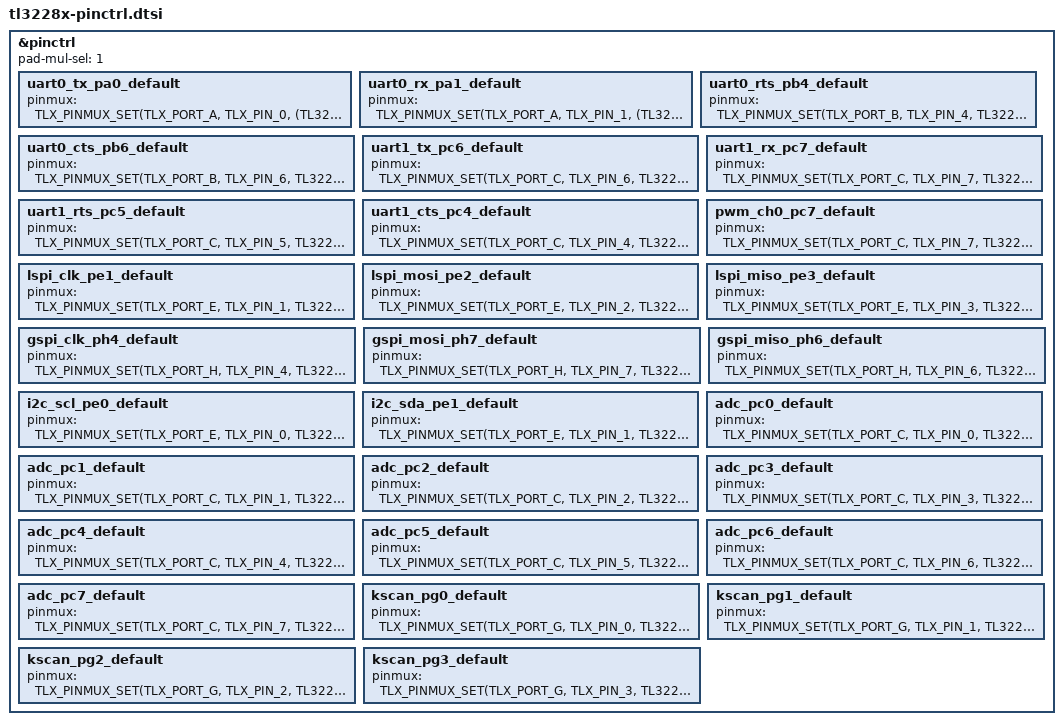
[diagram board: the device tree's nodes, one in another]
/*
 * Copyright (c) 2024 Telink Semiconductor
 *
 * SPDX-License-Identifier: Apache-2.0
 */

#include <zephyr/dt-bindings/pinctrl/tl322x-pinctrl.h>

&pinctrl {
	/* Set pad-mul-sel register value.
	 * Note: Pins functions below (pinmux = <...>) depend on this value.
	 */
	pad-mul-sel = <1>;

	/* UART0: TX(PA0), RX(PA1), RTS(PB4), CTS(PB6) */

	uart0_tx_pa0_default: uart0_tx_pa0_default {
		pinmux = <TLX_PINMUX_SET(TLX_PORT_A, TLX_PIN_0,
			(TL322X_FUNC_UART0_TX))>;
	};
	uart0_rx_pa1_default: uart0_rx_pa1_default {
		pinmux = <TLX_PINMUX_SET(TLX_PORT_A, TLX_PIN_1,
			(TL322X_FUNC_UART0_RTX_IO))>;
	};
	uart0_rts_pb4_default: uart0_rts_pb4_default {
		pinmux = <TLX_PINMUX_SET(TLX_PORT_B, TLX_PIN_4, TL322X_FUNC_UART0_RTS)>;
	};
	uart0_cts_pb6_default: uart0_cts_pb6_default {
		pinmux = <TLX_PINMUX_SET(TLX_PORT_B, TLX_PIN_6, TL322X_FUNC_UART0_CTS_I)>;
	};

	/* UART1: TX(PC6), RX(PC7), RTS(PC5), CTS(PC4) */

	uart1_tx_pc6_default: uart1_tx_pc6_default {
		pinmux = <TLX_PINMUX_SET(TLX_PORT_C, TLX_PIN_6, TL322X_FUNC_UART1_TX)>;
	};
	uart1_rx_pc7_default: uart1_rx_pc7_default {
		pinmux = <TLX_PINMUX_SET(TLX_PORT_C, TLX_PIN_7, TL322X_FUNC_UART1_RTX_IO)>;
	};
	uart1_rts_pc5_default: uart1_rts_pc5_default {
		pinmux = <TLX_PINMUX_SET(TLX_PORT_C, TLX_PIN_5, TL322X_FUNC_UART1_RTS)>;
	};
	uart1_cts_pc4_default: uart1_cts_pc4_default {
		pinmux = <TLX_PINMUX_SET(TLX_PORT_C, TLX_PIN_4, TL322X_FUNC_UART1_CTS_I)>;
	};

	/* PWM Channel 0 (PB7) */

	pwm_ch0_pc7_default: pwm_ch0_pc7_default {
		pinmux = <TLX_PINMUX_SET(TLX_PORT_C, TLX_PIN_7, TL322X_FUNC_PWM0)>;
	};

	/* LSPI: CLK(PE1), MOSI(PE2), MISO(PE3) */

	lspi_clk_pe1_default: lspi_clk_pe1_default {
		pinmux = <TLX_PINMUX_SET(TLX_PORT_E, TLX_PIN_1, TL322X_FUNC_DEFAULT)>;
	};
	lspi_mosi_pe2_default: lspi_mosi_pe2_default {
		pinmux = <TLX_PINMUX_SET(TLX_PORT_E, TLX_PIN_2, TL322X_FUNC_DEFAULT)>;
	};
	lspi_miso_pe3_default: lspi_miso_pe3_default {
		pinmux = <TLX_PINMUX_SET(TLX_PORT_E, TLX_PIN_3, TL322X_FUNC_DEFAULT)>;
	};

	/* GSPI: CLK(PF4), MOSI(PF7), MISO(PF6) */

	gspi_clk_ph4_default: gspi_clk_ph4_default {
		pinmux = <TLX_PINMUX_SET(TLX_PORT_H, TLX_PIN_4, TL322X_FUNC_GSPI_CK_IO)>;
	};
	gspi_mosi_ph7_default: gspi_mosi_ph7_default {
		pinmux = <TLX_PINMUX_SET(TLX_PORT_H, TLX_PIN_7, TL322X_FUNC_GSPI_MOSI_IO)>;
	};
	gspi_miso_ph6_default: gspi_miso_ph6_default {
		pinmux = <TLX_PINMUX_SET(TLX_PORT_H, TLX_PIN_6, TL322X_FUNC_GSPI_MISO_IO)>;
	};

	/* Define I2C pins: SCL(PE0), SDA(PE1) */

	i2c_scl_pe0_default: i2c_scl_pe0_default {
		pinmux = <TLX_PINMUX_SET(TLX_PORT_E, TLX_PIN_0, TL322X_FUNC_I2C_SCL_IO)>;
	};
	i2c_sda_pe1_default: i2c_sda_pe1_default {
		pinmux = <TLX_PINMUX_SET(TLX_PORT_E, TLX_PIN_1, TL322X_FUNC_I2C_SDA_IO)>;
	};

	/* Define ADC pins: PB0..PB7, PD0-PD1 */

	adc_pc0_default: adc_pc0_default {
		pinmux = <TLX_PINMUX_SET(TLX_PORT_C, TLX_PIN_0, TL322X_FUNC_DEFAULT)>;
	};
	adc_pc1_default: adc_pc1_default {
		pinmux = <TLX_PINMUX_SET(TLX_PORT_C, TLX_PIN_1, TL322X_FUNC_DEFAULT)>;
	};
	adc_pc2_default: adc_pc2_default {
		pinmux = <TLX_PINMUX_SET(TLX_PORT_C, TLX_PIN_2, TL322X_FUNC_DEFAULT)>;
	};
	adc_pc3_default: adc_pc3_default {
		pinmux = <TLX_PINMUX_SET(TLX_PORT_C, TLX_PIN_3, TL322X_FUNC_DEFAULT)>;
	};
	adc_pc4_default: adc_pc4_default {
		pinmux = <TLX_PINMUX_SET(TLX_PORT_C, TLX_PIN_4, TL322X_FUNC_DEFAULT)>;
	};
	adc_pc5_default: adc_pc5_default {
		pinmux = <TLX_PINMUX_SET(TLX_PORT_C, TLX_PIN_5, TL322X_FUNC_DEFAULT)>;
	};
	adc_pc6_default: adc_pc6_default {
		pinmux = <TLX_PINMUX_SET(TLX_PORT_C, TLX_PIN_6, TL322X_FUNC_DEFAULT)>;
	};
	adc_pc7_default: adc_pc7_default {
		pinmux = <TLX_PINMUX_SET(TLX_PORT_C, TLX_PIN_7, TL322X_FUNC_DEFAULT)>;
	};

	/* KSCAN: ROW(PG3, PG2), COL(PG1, PG0) */
	kscan_pg0_default: kscan_pg0_default {
		pinmux = <TLX_PINMUX_SET(TLX_PORT_G, TLX_PIN_0, TL322X_FUNC_DEFAULT)>;
	};
	kscan_pg1_default: kscan_pg1_default {
		pinmux = <TLX_PINMUX_SET(TLX_PORT_G, TLX_PIN_1, TL322X_FUNC_DEFAULT)>;
	};
	kscan_pg2_default: kscan_pg2_default {
		pinmux = <TLX_PINMUX_SET(TLX_PORT_G, TLX_PIN_2, TL322X_FUNC_DEFAULT)>;
	};
	kscan_pg3_default: kscan_pg3_default {
		pinmux = <TLX_PINMUX_SET(TLX_PORT_G, TLX_PIN_3, TL322X_FUNC_DEFAULT)>;
	};

};
